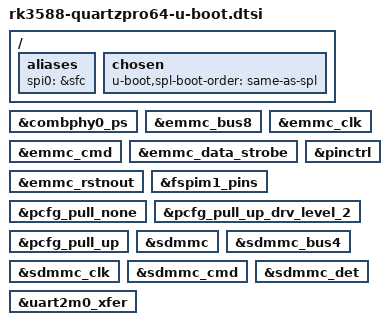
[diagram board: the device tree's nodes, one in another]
// SPDX-License-Identifier: (GPL-2.0+ OR MIT)
/*
 * Copyright (c) 2023 Collabora Ltd.
 */

#include "rk3588-u-boot.dtsi"
#include <dt-bindings/pinctrl/rockchip.h>
#include <dt-bindings/input/input.h>
#include <dt-bindings/gpio/gpio.h>

/ {
	aliases {
		spi0 = &sfc;
	};

	chosen {
		u-boot,spl-boot-order = "same-as-spl", &sdmmc;
	};
};

&combphy0_ps {
	status = "okay";
};

&emmc_bus8 {
	bootph-all;
};

&emmc_clk {
	bootph-all;
};

&emmc_cmd {
	bootph-all;
};

&emmc_data_strobe {
	bootph-all;
};

&emmc_rstnout {
	bootph-all;
};

&fspim1_pins {
	bootph-all;
};

&pinctrl {
	bootph-all;
};

&pcfg_pull_none {
	bootph-all;
};

&pcfg_pull_up_drv_level_2 {
	bootph-all;
};

&pcfg_pull_up {
	bootph-all;
};

&sdmmc {
	status = "okay";
};

&sdmmc_bus4 {
	bootph-all;
};

&sdmmc_clk {
	bootph-all;
};

&sdmmc_cmd {
	bootph-all;
};

&sdmmc_det {
	bootph-all;
};

/*
&sfc {
	bootph-pre-ram;
	u-boot,spl-sfc-no-dma;
};

&spi_flash {
	bootph-pre-ram;
};
*/

&uart2m0_xfer {
	bootph-all;
};
